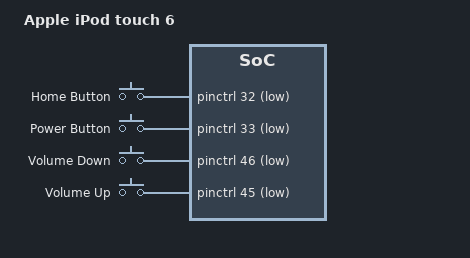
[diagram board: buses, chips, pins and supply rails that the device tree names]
// SPDX-License-Identifier: GPL-2.0+ OR MIT
/*
 * Apple iPod touch 6, N102, iPod7,1 (A1574)
 * Copyright (c) 2022, Konrad Dybcio <konradybcio@kernel.org>
 */

/dts-v1/;

#include "t7000.dtsi"
#include "t7000-common.dtsi"
#include "t7000-handheld.dtsi"
#include <dt-bindings/input/input.h>

/ {
	compatible = "apple,n102", "apple,t7000", "apple,arm-platform";
	model = "Apple iPod touch 6";
	chassis-type = "handset";

	gpio-keys {
		compatible = "gpio-keys";

		button-home {
			label = "Home Button";
			gpios = <&pinctrl 32 GPIO_ACTIVE_LOW>;
			linux,code = <KEY_HOMEPAGE>;
			wakeup-source;
		};

		button-power {
			label = "Power Button";
			gpios = <&pinctrl 33 GPIO_ACTIVE_LOW>;
			linux,code = <KEY_POWER>;
			wakeup-source;
		};

		button-voldown {
			label = "Volume Down";
			gpios = <&pinctrl 46 GPIO_ACTIVE_LOW>;
			linux,code = <KEY_VOLUMEDOWN>;
		};

		button-volup {
			label = "Volume Up";
			gpios = <&pinctrl 45 GPIO_ACTIVE_LOW>;
			linux,code = <KEY_VOLUMEUP>;
		};
	};
};
